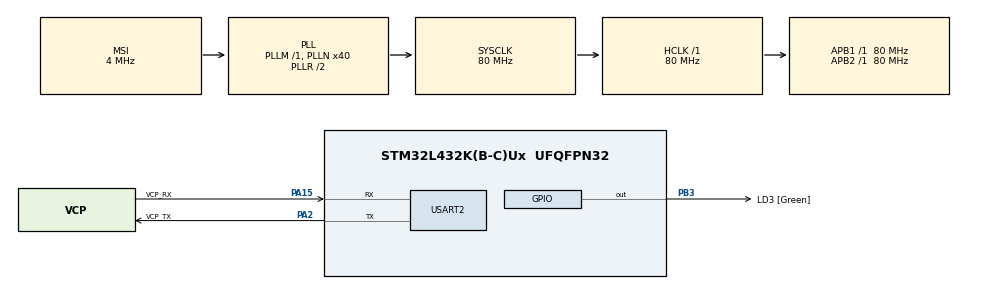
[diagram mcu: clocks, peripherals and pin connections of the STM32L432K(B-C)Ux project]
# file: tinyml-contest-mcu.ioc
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Mcu.Family=STM32L4
Mcu.Name=STM32L432K(B-C)Ux
Mcu.Package=UFQFPN32
NVIC.PriorityGroup=NVIC_PRIORITYGROUP_4
NVIC.TIM2_IRQn=true\:0\:0\:false\:false\:true\:true\:true\:true
PA0.GPIO_Label=MCO [High speed clock in]
PA0.Signal=RCC_CK_IN
PA13\ (JTMS-SWDIO).GPIO_Label=SWDIO
PA13\ (JTMS-SWDIO).Mode=Serial_Wire
PA13\ (JTMS-SWDIO).Signal=SYS_JTMS-SWDIO
PA14\ (JTCK-SWCLK).GPIO_Label=SWCLK
PA14\ (JTCK-SWCLK).Mode=Serial_Wire
PA14\ (JTCK-SWCLK).Signal=SYS_JTCK-SWCLK
PA15\ (JTDI).GPIO_Label=VCP_RX
PA15\ (JTDI).Mode=Asynchronous
PA15\ (JTDI).Signal=USART2_RX
PA2.GPIO_Label=VCP_TX
PA2.Mode=Asynchronous
PA2.Signal=USART2_TX
PB3\ (JTDO-TRACESWO).GPIO_Label=LD3 [Green]
PB3\ (JTDO-TRACESWO).Signal=GPIO_Output
PC14-OSC32_IN\ (PC14).Mode=LSE-External-Oscillator
PC14-OSC32_IN\ (PC14).Signal=RCC_OSC32_IN
PC15-OSC32_OUT\ (PC15).Mode=LSE-External-Oscillator
PC15-OSC32_OUT\ (PC15).Signal=RCC_OSC32_OUT
ProjectManager.HeapSize=0x800
ProjectManager.StackSize=0x800
ProjectManager.TargetToolchain=MDK-ARM V5.32
RCC.ADCFreq_Value=16000000
RCC.AHBFreq_Value=80000000
RCC.APB1Freq_Value=80000000
RCC.APB1TimFreq_Value=80000000
RCC.APB2Freq_Value=80000000
RCC.APB2TimFreq_Value=80000000
RCC.CortexFreq_Value=80000000
RCC.HCLKFreq_Value=80000000
RCC.HSE_VALUE=8000000
RCC.HSI16_VALUE=16000000
RCC.HSI48_VALUE=48000000
RCC.HSI_VALUE=16000000
RCC.MSI_VALUE=4000000
RCC.PLLMUL=RCC_PLLMUL_4
RCC.PLLN=40
RCC.SYSCLKFreq_VALUE=80000000
RCC.SYSCLKSource=RCC_SYSCLKSOURCE_PLLCLK
RCC.USBFreq_Value=16000000
RCC.VCOOutputFreq_Value=160000000
TIM2.AutoReloadPreload=TIM_AUTORELOAD_PRELOAD_ENABLE
TIM2.Period=5000
TIM2.Prescaler=9
USART2.VirtualMode-Asynchronous=VM_ASYNC
VP_CRC_VS_CRC.Mode=CRC_Activate
VP_TIM2_VS_ClockSourceINT.Mode=Internal
board=NUCLEO-L432KC

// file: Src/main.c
/* USER CODE BEGIN Header */
/**
  ******************************************************************************
  * @file           : main.c
  * @brief          : Main program body
  ******************************************************************************
  * @attention
  *
  * <h2><center>&copy; Copyright (c) 2022 STMicroelectronics.
  * All rights reserved.</center></h2>
  *
  * This software component is licensed by ST under Ultimate Liberty license
  * SLA0044, the "License"; You may not use this file except in compliance with
  * the License. You may obtain a copy of the License at:
  *                             www.st.com/SLA0044
  *
  ******************************************************************************
  */
/* USER CODE END Header */
#include "main.h"
#include "crc.h"
#include "tim.h"
#include "usart.h"
#include "gpio.h"

/* USER CODE BEGIN Includes */
#include "stdio.h"
#include "nnom_port.h"
#include "nnom.h"
#include "weights_contest.h"

/* USER CODE END Includes */

void SystemClock_Config(void);
/* USER CODE BEGIN PFP */

uint32_t getCurrentMicros(void)
{
	LL_SYSTICK_IsActiveCounterFlag();
	uint32_t m = HAL_GetTick();
	const uint32_t tms = SysTick->LOAD + 1;
	__IO uint32_t u = tms - SysTick->VAL;
	if (LL_SYSTICK_IsActiveCounterFlag())
	{
		m = HAL_GetTick();
		u = tms - SysTick->VAL;
	}
	return (m*1000+(u*1000)/tms);
}

int quantise_8bit(char qbit, float input)
{
	int qi = input * (1<<qbit); // only work with decimal bit >= 0
	qi = qi > 127? 127 : qi; 			// to 8bit range
	qi = qi <-128? -128 : qi;
	return qi;
}

/* USER CODE END PFP */

/* USER CODE BEGIN 0 */
float input[1][1250][1]={0};
float result[2]={0};

#ifdef NNOM_USING_STATIC_MEMORY
uint8_t static_buf[1024 * 48];
#endif

/* USER CODE END 0 */

int main(void)
{
  /* USER CODE BEGIN 1 */
  float input_tmp;
  int status=0;
  double vector[2] = {0};
	double start_time = 0;
	double end_time = 0;
	int rst = 0;
  /* USER CODE END 1 */

  /* MCU Configuration--------------------------------------------------------*/

  /* Reset of all peripherals, Initializes the Flash interface and the Systick. */
  HAL_Init();

  /* Configure the system clock */
  SystemClock_Config();

  /* Initialize all configured peripherals */
  MX_GPIO_Init();
  MX_TIM2_Init();
  MX_USART2_UART_Init();
  MX_CRC_Init();
  /* USER CODE BEGIN 2 */
	nnom_model_t *model;

#ifdef NNOM_USING_STATIC_MEMORY
    nnom_set_static_buf(static_buf, sizeof(static_buf));
#endif //NNOM_USING_STATIC_BUF

	model = nnom_model_create();				// create NNoM model

  /* USER CODE END 2 */

  /* Infinite loop */
  /* USER CODE BEGIN WHILE */
  while (1)
  {
		 // Send the code "begin" to tell the upper computer that it can start sending a set of test data.
    printf("begin");
    for(int16_t i=0;i<1;i++)
    {
      for(int16_t j=0;j<1250;j++)
      {
        for(int16_t k=0;k<1;k++)
        {
          // Receive test data from serial port and save to input[]
          scanf("%f",&input_tmp);
          //input[i][j][k]=input_tmp;
					nnom_input_data[j] = quantise_8bit(7, input_tmp);
        }

      }
    }
    HAL_Delay(1);
    //Run the model and get results
	start_time = getCurrentMicros();

		model_run(model);
		rst = nnom_output_data[0]>=64? 1: 0; // 0-127

	end_time = getCurrentMicros();
    // Send the code "ok" to tell the upper computer that inference is done and ready to send results.
    printf("ok");
    HAL_Delay(1);
    // Wait for the upper computer to send status 200, indicating that the code "ok" has been received
    scanf("%d",&status);
    if(status==200)
    {
      // Sending results to the upper computer
      if(rst)
        printf("1,%.6f", (double)(end_time-start_time)/(double)1000000);
      else
        printf("0,%.6f", (double)(end_time-start_time)/(double)1000000);
      HAL_Delay(30);
    }

    /* USER CODE END WHILE */

  }
}

void SystemClock_Config(void)
{
  RCC_OscInitTypeDef RCC_OscInitStruct = {0};
  RCC_ClkInitTypeDef RCC_ClkInitStruct = {0};

  /** Configure the main internal regulator output voltage
  */
  if (HAL_PWREx_ControlVoltageScaling(PWR_REGULATOR_VOLTAGE_SCALE1) != HAL_OK)
  {
    Error_Handler();
  }

  /** Configure LSE Drive Capability
  */
  HAL_PWR_EnableBkUpAccess();
  __HAL_RCC_LSEDRIVE_CONFIG(RCC_LSEDRIVE_LOW);

  /** Initializes the RCC Oscillators according to the specified parameters
  * in the RCC_OscInitTypeDef structure.
  */
  RCC_OscInitStruct.OscillatorType = RCC_OSCILLATORTYPE_LSE|RCC_OSCILLATORTYPE_MSI;
  RCC_OscInitStruct.LSEState = RCC_LSE_ON;
  RCC_OscInitStruct.MSIState = RCC_MSI_ON;
  RCC_OscInitStruct.MSICalibrationValue = 0;
  RCC_OscInitStruct.MSIClockRange = RCC_MSIRANGE_6;
  RCC_OscInitStruct.PLL.PLLState = RCC_PLL_ON;
  RCC_OscInitStruct.PLL.PLLSource = RCC_PLLSOURCE_MSI;
  RCC_OscInitStruct.PLL.PLLM = 1;
  RCC_OscInitStruct.PLL.PLLN = 40;
  RCC_OscInitStruct.PLL.PLLP = RCC_PLLP_DIV7;
  RCC_OscInitStruct.PLL.PLLQ = RCC_PLLQ_DIV2;
  RCC_OscInitStruct.PLL.PLLR = RCC_PLLR_DIV2;
  if (HAL_RCC_OscConfig(&RCC_OscInitStruct) != HAL_OK)
  {
    Error_Handler();
  }

  /** Initializes the CPU, AHB and APB buses clocks
  */
  RCC_ClkInitStruct.ClockType = RCC_CLOCKTYPE_HCLK|RCC_CLOCKTYPE_SYSCLK
                              |RCC_CLOCKTYPE_PCLK1|RCC_CLOCKTYPE_PCLK2;
  RCC_ClkInitStruct.SYSCLKSource = RCC_SYSCLKSOURCE_PLLCLK;
  RCC_ClkInitStruct.AHBCLKDivider = RCC_SYSCLK_DIV1;
  RCC_ClkInitStruct.APB1CLKDivider = RCC_HCLK_DIV1;
  RCC_ClkInitStruct.APB2CLKDivider = RCC_HCLK_DIV1;

  if (HAL_RCC_ClockConfig(&RCC_ClkInitStruct, FLASH_LATENCY_4) != HAL_OK)
  {
    Error_Handler();
  }

  /** Enable MSI Auto calibration
  */
  HAL_RCCEx_EnableMSIPLLMode();
}

void Error_Handler(void)
{
  __disable_irq();
  while (1)
  {
  }
}
